VERSION ""

NS_ :

BS_:

BU_:

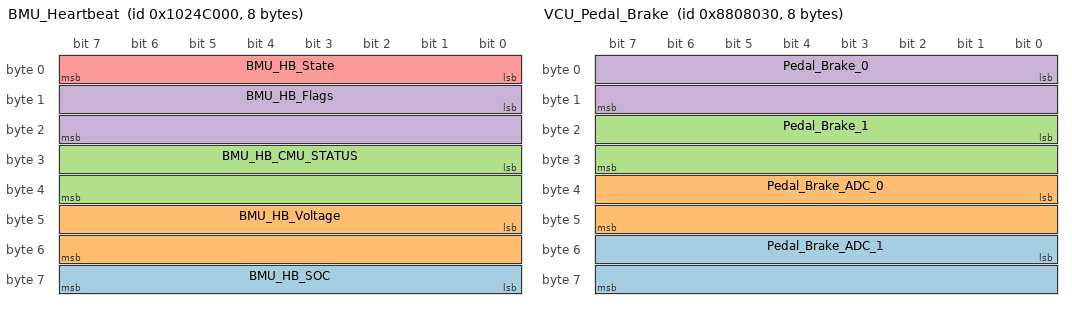
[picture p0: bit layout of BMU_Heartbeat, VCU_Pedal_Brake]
BO_ 270843904 BMU_Heartbeat: 8 Vector__XXX
 SG_ BMU_HB_SOC : 56|8@1+ (1,0) [0|0] "" Vector__XXX
 SG_ BMU_HB_Voltage : 40|16@1+ (1,0) [0|0] "" Vector__XXX
 SG_ BMU_HB_CMU_STATUS : 24|16@1- (1,0) [0|0] "" Vector__XXX
 SG_ BMU_HB_Flags : 8|16@1+ (1,0) [0|0] "" Vector__XXX
 SG_ BMU_HB_State : 0|8@1+ (1,0) [0|0] "" Vector__XXX

BO_ 142639216 VCU_IMU_Accel_0: 8 Vector__XXX
 SG_ IMU_Accel_Scale_0 : 7|16@0- (1,0) [0|0] "" Vector__XXX

BO_ 142639152 VCU_Pedal_Brake: 8 Vector__XXX
 SG_ Pedal_Brake_ADC_1 : 48|16@1+ (1,0) [0|4095] "" Vector__XXX
 SG_ Pedal_Brake_ADC_0 : 32|16@1+ (1,0) [0|4095] "" Vector__XXX
 SG_ Pedal_Brake_1 : 16|16@1+ (1,0) [0|1000] "" Vector__XXX
 SG_ Pedal_Brake_0 : 0|16@1+ (1,0) [0|1000] "" Vector__XXX

BO_ 142639136 VCU_Pedal_Accel: 4 Vector__XXX
 SG_ Pedal_Accel_1 : 16|16@1+ (1,0) [0|1000] "" Vector__XXX
 SG_ Pedal_Accel_0 : 0|16@1+ (1,0) [0|1000] "" Vector__XXX

BA_DEF_  "BusType" STRING ;
BA_DEF_DEF_  "BusType" "CAN";
